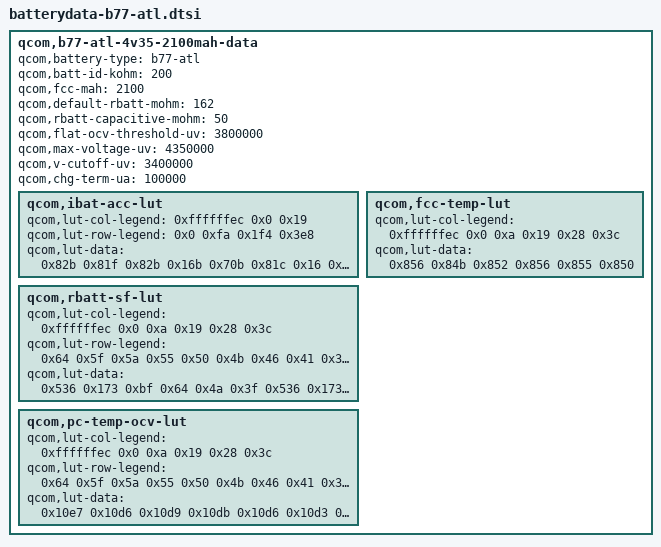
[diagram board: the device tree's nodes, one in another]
/* Copyright (c) 2020, The Linux Foundation. All rights reserved.
*  Copyright (c) 2020, the_shahnawaz_sheikh (sheikhshahnawaz41299).
*
* This program is free software; you can redistribute it and/or modify
* it under the terms of the GNU General Public License version 2 and
* only version 2 as published by the Free Software Foundation.
*
* This program is distributed in the hope that it will be useful,
* but WITHOUT ANY WARRANTY; without even the implied warranty of
* MERCHANTABILITY or FITNESS FOR A PARTICULAR PURPOSE.  See the
* GNU General Public License for more details.
*/

qcom,b77-atl-4v35-2100mah-data {
			qcom,battery-type = "b77-atl";
			qcom,batt-id-kohm = <200>;
			qcom,fcc-mah = <2100>;
			qcom,default-rbatt-mohm = <162>;
			qcom,rbatt-capacitive-mohm = <50>;
			qcom,flat-ocv-threshold-uv = <3800000>;
			qcom,max-voltage-uv = <4350000>;
			qcom,v-cutoff-uv = <3400000>;
			qcom,chg-term-ua = <100000>;

			qcom,ibat-acc-lut {
				qcom,lut-col-legend = <0xffffffec 0x0 0x19>;
				qcom,lut-row-legend = <0x0 0xfa 0x1f4 0x3e8>;
				qcom,lut-data = <0x82b 0x81f 0x82b 0x16b 0x70b 0x81c 0x16 0x5ac 0x80b 0x6 0x42a 0x7bf>;
			};

			qcom,rbatt-sf-lut {
				qcom,lut-col-legend = <0xffffffec 0x0 0xa 0x19 0x28 0x3c>;
				qcom,lut-row-legend = <0x64 0x5f 0x5a 0x55 0x50 0x4b 0x46 0x41 0x3c 0x37 0x32 0x2d 0x28 0x23 0x1e 0x19 0x14 0x10 0xd 0xb 0xa 0x9 0x8 0x7 0x6 0x5 0x4 0x3 0x2 0x1 0x0>;
				qcom,lut-data = <0x536 0x173 0xbf 0x64 0x4a 0x3f 0x536 0x173 0xbf 0x64 0x4a 0x3f 0x4df 0x171 0xc1 0x66 0x4c 0x3f 0x4b2 0x16b 0xc6 0x69 0x4e 0x41 0x47e 0x16b 0xc9 0x6e 0x51 0x43 0x46c 0x158 0xd0 0x74 0x54 0x45 0x46f 0x13e 0xc4 0x79 0x59 0x47 0x470 0x13e 0xba 0x80 0x5e 0x4a 0x47c 0x13a 0xaf 0x77 0x61 0x4e 0x499 0x138 0xab 0x64 0x4f 0x43 0x4c5 0x139 0xab 0x61 0x4a 0x40 0x4fd 0x13f 0xac 0x62 0x4b 0x41 0x544 0x14e 0xad 0x65 0x4e 0x43 0x598 0x164 0xb4 0x66 0x51 0x46 0x5fe 0x181 0xc0 0x6a 0x50 0x45 0x68d 0x1a5 0xce 0x6c 0x4e 0x40 0x7ab 0x1dc 0xdc 0x6c 0x4c 0x40 0x941 0x223 0xeb 0x6e 0x4e 0x41 0xa71 0x26a 0xf8 0x6d 0x4d 0x40 0x9ed 0x26c 0xfe 0x6d 0x4c 0x40 0xaef 0x289 0x10a 0x6f 0x4e 0x41 0xc3b 0x2b1 0x11b 0x73 0x51 0x43 0xddd 0x2e0 0x130 0x79 0x54 0x44 0xfde 0x314 0x14b 0x7f 0x57 0x46 0x1280 0x353 0x168 0x86 0x59 0x46 0x160f 0x394 0x188 0x8a 0x57 0x44 0x1aff 0x3e3 0x1ac 0x8c 0x57 0x44 0x226f 0x44c 0x1ea 0x97 0x5c 0x47 0x313c 0x4f5 0x256 0xae 0x66 0x50 0x66f8 0xbb5 0xd24 0xfd 0xa1 0x8d 0x66f8 0xbb5 0xd24 0xfd 0xa1 0x8d>;
			};

			qcom,fcc-temp-lut {
				qcom,lut-col-legend = <0xffffffec 0x0 0xa 0x19 0x28 0x3c>;
				qcom,lut-data = <0x856 0x84b 0x852 0x856 0x855 0x850>;
			};

			qcom,pc-temp-ocv-lut {
				qcom,lut-col-legend = <0xffffffec 0x0 0xa 0x19 0x28 0x3c>;
				qcom,lut-row-legend = <0x64 0x5f 0x5a 0x55 0x50 0x4b 0x46 0x41 0x3c 0x37 0x32 0x2d 0x28 0x23 0x1e 0x19 0x14 0x10 0xd 0xb 0xa 0x9 0x8 0x7 0x6 0x5 0x4 0x3 0x2 0x1 0x0>;
				qcom,lut-data = <0x10e7 0x10d6 0x10d9 0x10db 0x10d6 0x10d3 0x107d 0x108a 0x1095 0x109b 0x1099 0x1096 0x102d 0x104b 0x105a 0x1060 0x105f 0x105c 0xfed 0x1012 0x1023 0x1029 0x1028 0x1025 0xf9d 0xfdf 0xff0 0xff6 0xff4 0xff1 0xf63 0xfa0 0xfbc 0xfc5 0xfc4 0xfc1 0xf3a 0xf69 0xf85 0xf95 0xf97 0xf94 0xf14 0xf43 0xf58 0xf6f 0xf6f 0xf6c 0xef7 0xf1f 0xf2e 0xf42 0xf47 0xf46 0xee2 0xf00 0xf0d 0xf15 0xf17 0xf17 0xed2 0xee6 0xef2 0xef7 0xef8 0xef8 0xec5 0xed2 0xedc 0xee1 0xee2 0xee1 0xeb8 0xec4 0xeca 0xecf 0xed0 0xecf 0xea9 0xeb9 0xebf 0xec1 0xec1 0xec0 0xe9a 0xead 0xeb5 0xeb7 0xeb3 0xeae 0xe88 0xe9c 0xeaa 0xeaa 0xea3 0xe96 0xe71 0xe86 0xe95 0xe97 0xe8e 0xe81 0xe5c 0xe75 0xe7e 0xe7f 0xe76 0xe6b 0xe49 0xe69 0xe68 0xe67 0xe60 0xe55 0xe3c 0xe60 0xe5f 0xe5e 0xe58 0xe4d 0xe32 0xe5a 0xe5b 0xe5b 0xe56 0xe4b 0xe27 0xe54 0xe57 0xe59 0xe53 0xe49 0xe1a 0xe4d 0xe53 0xe56 0xe51 0xe46 0xe09 0xe44 0xe4e 0xe51 0xe4c 0xe42 0xdf6 0xe36 0xe43 0xe49 0xe43 0xe37 0xddc 0xe1b 0xe2d 0xe32 0xe28 0xe1b 0xdba 0xdef 0xe01 0xe06 0xdf8 0xdea 0xd89 0xdae 0xdbf 0xdc6 0xdb7 0xdaa 0xd3f 0xd4e 0xd62 0xd6e 0xd5e 0xd53 0xcc7 0xcb0 0xcd3 0xce8 0xcd5 0xcc7 0xbb8 0xbd6 0xbb8 0xbb8 0xbb8 0xbb8>;
			};
		};
